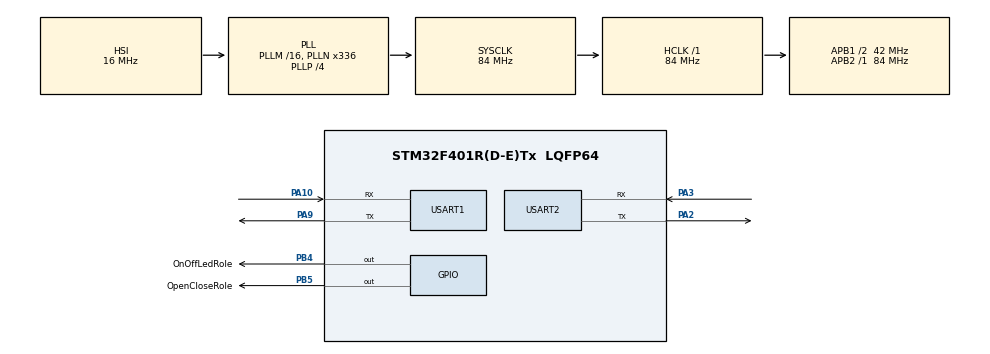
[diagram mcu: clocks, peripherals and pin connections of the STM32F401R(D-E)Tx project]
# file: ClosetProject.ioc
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Mcu.Family=STM32F4
RCC.CortexFreq_Value=84000000
PA10.Mode=Asynchronous
PH1\ -\ OSC_OUT.Mode=HSE-External-Oscillator
RCC.APB1CLKDivider=RCC_HCLK_DIV2
NVIC.USART2_IRQn=true\:0\:0\:false\:false\:true\:true\:true
RCC.SYSCLKSource=RCC_SYSCLKSOURCE_PLLCLK
ProjectManager.StackSize=0x400
PA13.Signal=SYS_JTMS-SWDIO
PA3.Mode=Asynchronous
PA9.Mode=Asynchronous
PH0\ -\ OSC_IN.Mode=HSE-External-Oscillator
PH0\ -\ OSC_IN.Signal=RCC_OSC_IN
ProjectManager.TargetToolchain=STM32CubeIDE
RCC.HCLKFreq_Value=84000000
RCC.APB2TimFreq_Value=84000000
PA9.Signal=USART1_TX
RCC.LSE_VALUE=32768
RCC.AHBFreq_Value=84000000
RCC.HSE_VALUE=8000000
PH1\ -\ OSC_OUT.Signal=RCC_OSC_OUT
board=NUCLEO-F401RE
RCC.VCOOutputFreq_Value=336000000
RCC.APB2Freq_Value=84000000
PB4.GPIO_Label=OnOffLedRole
PA14.Mode=Serial_Wire
PA13.Mode=Serial_Wire
Mcu.Name=STM32F401R(D-E)Tx
PA2.Signal=USART2_TX
RCC.48MHZClocksFreq_Value=48000000
RCC.SYSCLKFreq_VALUE=84000000
Mcu.Package=LQFP64
PB5.Signal=GPIO_Output
USART2.VirtualMode=VM_ASYNC
USART1.VirtualMode=VM_ASYNC
PA10.Signal=USART1_RX
PA14.Signal=SYS_JTCK-SWCLK
ProjectManager.HeapSize=0x200
RCC.HSI_VALUE=16000000
RCC.PLLP=RCC_PLLP_DIV4
RCC.PLLQ=7
NVIC.PriorityGroup=NVIC_PRIORITYGROUP_0
PB5.GPIO_Label=OpenCloseRole
RCC.PLLN=336
RCC.APB1TimFreq_Value=84000000
PA2.Mode=Asynchronous
NVIC.USART1_IRQn=true\:0\:0\:false\:false\:true\:true\:true
RCC.APB1Freq_Value=42000000
PB4.Signal=GPIO_Output
PA3.Signal=USART2_RX

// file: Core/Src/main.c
/* USER CODE BEGIN Header */
/**
  ******************************************************************************
  * @file           : main.c
  * @brief          : Main program body
  ******************************************************************************
  * @attention
  *
  * <h2><center>&copy; Copyright (c) 2021 STMicroelectronics.
  * All rights reserved.</center></h2>
  *
  * This software component is licensed by ST under BSD 3-Clause license,
  * the "License"; You may not use this file except in compliance with the
  * License. You may obtain a copy of the License at:
  *                        opensource.org/licenses/BSD-3-Clause
  *
  ******************************************************************************
  */
/* USER CODE END Header */
#include "main.h"
#include "ClosetParse.h"
#include "WifiConnectDataParse.h"

/* USER CODE BEGIN PTD */

uint8_t RxBufferCnt=0;

/*UART2*/
uint8_t RxData=0;
uint8_t RxData1 =0;
uint8_t flag =0;
char ID[] = "Luhmann";
char PW[] = "Luhmann2995@";
char TxBufferk[4]="AT\r\n";
/* USER CODE END PTD */

UART_HandleTypeDef huart1;
UART_HandleTypeDef huart2;

void SystemClock_Config(void);
static void MX_GPIO_Init(void);
static void MX_USART2_UART_Init(void);
static void MX_USART1_UART_Init(void);

void HAL_UART_RxCpltCallback(UART_HandleTypeDef *huart)
{
	if(huart == &huart2)
	{
		ESP_Gelen_Data[RxBufferCnt++]= RxData;
		if(RxBufferCnt>254)
			RxBufferCnt=0;

		HAL_UART_Receive_IT(&huart2,&RxData,1);
	}
	else if(huart == &huart1)
	{
		ESP_Gelen_Data1[RxBufferCnt1++]= RxData1;
		if(RxBufferCnt1>254)
			RxBufferCnt1=0;

		HAL_UART_Receive_IT(&huart1,&RxData1,1);
	}

}
int main(void)
{

  /* MCU Configuration--------------------------------------------------------*/

  /* Reset of all peripherals, Initializes the Flash interface and the Systick. */

	HAL_Init();

  /* Configure the system clock */
  SystemClock_Config();

  /* Initialize all configured peripherals */
  MX_GPIO_Init();
  MX_USART2_UART_Init();
  MX_USART1_UART_Init();
  /* USER CODE BEGIN 2 */
  /* USER CODE BEGIN 2 */
  	HAL_UART_Receive_IT(&huart1,&RxData1,1);
  	HAL_UART_Receive_IT(&huart2,&RxData,1);

  /* USER CODE END 2 */

  /* Infinite loop */
  /* USER CODE BEGIN WHILE */
  while (1)
  {
	 /* HAL_UART_Transmit(&huart2, (uint8_t*)TxBufferk, 4, 100);
	  HAL_Delay(1000);*/

	  DataConnectionControl();
	  PcDolapAcKapat();
	  HAL_Delay(1);

    /* USER CODE END WHILE */

  }
}

void SystemClock_Config(void)
{
  RCC_OscInitTypeDef RCC_OscInitStruct = {0};
  RCC_ClkInitTypeDef RCC_ClkInitStruct = {0};

  /** Configure the main internal regulator output voltage
  */
  __HAL_RCC_PWR_CLK_ENABLE();
  __HAL_PWR_VOLTAGESCALING_CONFIG(PWR_REGULATOR_VOLTAGE_SCALE2);
  /** Initializes the RCC Oscillators according to the specified parameters
  * in the RCC_OscInitTypeDef structure.
  */
  RCC_OscInitStruct.OscillatorType = RCC_OSCILLATORTYPE_HSI;
  RCC_OscInitStruct.HSIState = RCC_HSI_ON;
  RCC_OscInitStruct.HSICalibrationValue = RCC_HSICALIBRATION_DEFAULT;
  RCC_OscInitStruct.PLL.PLLState = RCC_PLL_ON;
  RCC_OscInitStruct.PLL.PLLSource = RCC_PLLSOURCE_HSI;
  RCC_OscInitStruct.PLL.PLLM = 16;
  RCC_OscInitStruct.PLL.PLLN = 336;
  RCC_OscInitStruct.PLL.PLLP = RCC_PLLP_DIV4;
  RCC_OscInitStruct.PLL.PLLQ = 7;
  if (HAL_RCC_OscConfig(&RCC_OscInitStruct) != HAL_OK)
  {
    Error_Handler();
  }
  /** Initializes the CPU, AHB and APB buses clocks
  */
  RCC_ClkInitStruct.ClockType = RCC_CLOCKTYPE_HCLK|RCC_CLOCKTYPE_SYSCLK
                              |RCC_CLOCKTYPE_PCLK1|RCC_CLOCKTYPE_PCLK2;
  RCC_ClkInitStruct.SYSCLKSource = RCC_SYSCLKSOURCE_PLLCLK;
  RCC_ClkInitStruct.AHBCLKDivider = RCC_SYSCLK_DIV1;
  RCC_ClkInitStruct.APB1CLKDivider = RCC_HCLK_DIV2;
  RCC_ClkInitStruct.APB2CLKDivider = RCC_HCLK_DIV1;

  if (HAL_RCC_ClockConfig(&RCC_ClkInitStruct, FLASH_LATENCY_2) != HAL_OK)
  {
    Error_Handler();
  }
}

static void MX_USART1_UART_Init(void)
{

  huart1.Instance = USART1;
  huart1.Init.BaudRate = 115200;
  huart1.Init.WordLength = UART_WORDLENGTH_8B;
  huart1.Init.StopBits = UART_STOPBITS_1;
  huart1.Init.Parity = UART_PARITY_NONE;
  huart1.Init.Mode = UART_MODE_TX_RX;
  huart1.Init.HwFlowCtl = UART_HWCONTROL_NONE;
  huart1.Init.OverSampling = UART_OVERSAMPLING_16;
  if (HAL_UART_Init(&huart1) != HAL_OK)
  {
    Error_Handler();
  }

}

static void MX_USART2_UART_Init(void)
{

  huart2.Instance = USART2;
  huart2.Init.BaudRate = 115200;
  huart2.Init.WordLength = UART_WORDLENGTH_8B;
  huart2.Init.StopBits = UART_STOPBITS_1;
  huart2.Init.Parity = UART_PARITY_NONE;
  huart2.Init.Mode = UART_MODE_TX_RX;
  huart2.Init.HwFlowCtl = UART_HWCONTROL_NONE;
  huart2.Init.OverSampling = UART_OVERSAMPLING_16;
  if (HAL_UART_Init(&huart2) != HAL_OK)
  {
    Error_Handler();
  }

}

static void MX_GPIO_Init(void)
{
  GPIO_InitTypeDef GPIO_InitStruct = {0};

  /* GPIO Ports Clock Enable */
  __HAL_RCC_GPIOH_CLK_ENABLE();
  __HAL_RCC_GPIOA_CLK_ENABLE();
  __HAL_RCC_GPIOB_CLK_ENABLE();

  /*Configure GPIO pin Output Level */
  HAL_GPIO_WritePin(GPIOB, OnOffLedRole_Pin|OpenCloseRole_Pin, GPIO_PIN_RESET);

  /*Configure GPIO pins : OnOffLedRole_Pin OpenCloseRole_Pin */
  GPIO_InitStruct.Pin = OnOffLedRole_Pin|OpenCloseRole_Pin;
  GPIO_InitStruct.Mode = GPIO_MODE_OUTPUT_PP;
  GPIO_InitStruct.Pull = GPIO_NOPULL;
  GPIO_InitStruct.Speed = GPIO_SPEED_FREQ_LOW;
  HAL_GPIO_Init(GPIOB, &GPIO_InitStruct);

}

void Error_Handler(void)
{
  __disable_irq();
  while (1)
  {
  }
}

/************************ (C) COPYRIGHT STMicroelectronics *****END OF FILE****/
